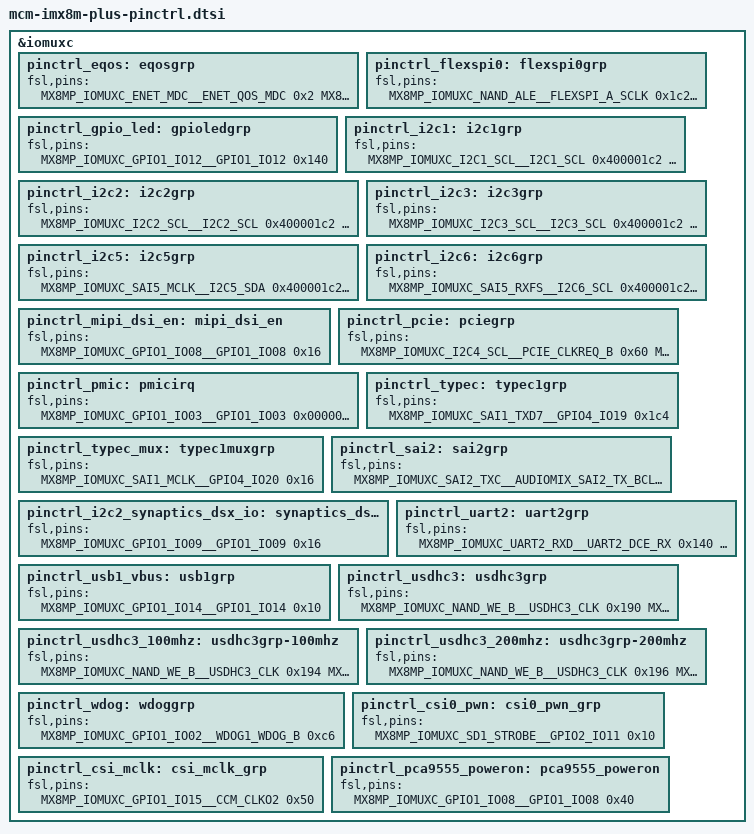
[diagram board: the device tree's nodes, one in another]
#include <dt-bindings/usb/pd.h>
#include "../freescale/imx8mp.dtsi"

&iomuxc {

	pinctrl_eqos: eqosgrp {
		fsl,pins = <
			MX8MP_IOMUXC_ENET_MDC__ENET_QOS_MDC	0x2
			MX8MP_IOMUXC_ENET_MDIO__ENET_QOS_MDIO	0x2
			MX8MP_IOMUXC_ENET_RD0__ENET_QOS_RGMII_RD0	0x90
			MX8MP_IOMUXC_ENET_RD1__ENET_QOS_RGMII_RD1	0x90
			MX8MP_IOMUXC_ENET_RD2__ENET_QOS_RGMII_RD2	0x90
			MX8MP_IOMUXC_ENET_RD3__ENET_QOS_RGMII_RD3	0x90
			MX8MP_IOMUXC_ENET_RXC__CCM_ENET_QOS_CLOCK_GENERATE_RX_CLK	0x90
			MX8MP_IOMUXC_ENET_RX_CTL__ENET_QOS_RGMII_RX_CTL	0x90
			MX8MP_IOMUXC_ENET_TD0__ENET_QOS_RGMII_TD0		0x16
			MX8MP_IOMUXC_ENET_TD1__ENET_QOS_RGMII_TD1		0x16
			MX8MP_IOMUXC_ENET_TD2__ENET_QOS_RGMII_TD2		0x16
			MX8MP_IOMUXC_ENET_TD3__ENET_QOS_RGMII_TD3		0x16
			MX8MP_IOMUXC_ENET_TX_CTL__ENET_QOS_RGMII_TX_CTL	0x16
			MX8MP_IOMUXC_ENET_TXC__CCM_ENET_QOS_CLOCK_GENERATE_TX_CLK	0x16
			MX8MP_IOMUXC_GPIO1_IO10__GPIO1_IO10				0x10
		>;
	};

	pinctrl_flexspi0: flexspi0grp {
		fsl,pins = <
			MX8MP_IOMUXC_NAND_ALE__FLEXSPI_A_SCLK		0x1c2
			MX8MP_IOMUXC_NAND_CE0_B__FLEXSPI_A_SS0_B	0x82
			MX8MP_IOMUXC_NAND_DATA00__FLEXSPI_A_DATA00	0x82
			MX8MP_IOMUXC_NAND_DATA01__FLEXSPI_A_DATA01	0x82
			MX8MP_IOMUXC_NAND_DATA02__FLEXSPI_A_DATA02	0x82
			MX8MP_IOMUXC_NAND_DATA03__FLEXSPI_A_DATA03	0x82
		>;
	};

	pinctrl_gpio_led: gpioledgrp {
		fsl,pins = <
			MX8MP_IOMUXC_GPIO1_IO12__GPIO1_IO12	0x140
		>;
	};

	pinctrl_i2c1: i2c1grp {
		fsl,pins = <
			MX8MP_IOMUXC_I2C1_SCL__I2C1_SCL		0x400001c2
			MX8MP_IOMUXC_I2C1_SDA__I2C1_SDA		0x400001c2
		>;
	};

	pinctrl_i2c2: i2c2grp {
		fsl,pins = <
			MX8MP_IOMUXC_I2C2_SCL__I2C2_SCL			0x400001c2
			MX8MP_IOMUXC_I2C2_SDA__I2C2_SDA			0x400001c2
		>;
	};

	pinctrl_i2c3: i2c3grp {
		fsl,pins = <
			MX8MP_IOMUXC_I2C3_SCL__I2C3_SCL			0x400001c2
			MX8MP_IOMUXC_I2C3_SDA__I2C3_SDA			0x400001c2
		>;
	};

	pinctrl_i2c5: i2c5grp {
		fsl,pins = <
			MX8MP_IOMUXC_SAI5_MCLK__I2C5_SDA		0x400001c2
			MX8MP_IOMUXC_SAI5_RXD0__I2C5_SCL		0x400001c2
		>;
	};

	pinctrl_i2c6: i2c6grp {
		fsl,pins = <
			MX8MP_IOMUXC_SAI5_RXFS__I2C6_SCL		0x400001c2
			MX8MP_IOMUXC_SAI5_RXC__I2C6_SDA			0x400001c2
		>;
	};

	pinctrl_mipi_dsi_en: mipi_dsi_en {
		fsl,pins = <
			MX8MP_IOMUXC_GPIO1_IO08__GPIO1_IO08	0x16
		>;
	};

	pinctrl_pcie: pciegrp {
		fsl,pins = <
			MX8MP_IOMUXC_I2C4_SCL__PCIE_CLKREQ_B		0x60
			MX8MP_IOMUXC_I2C4_SDA__GPIO5_IO21		0x10
		>;
	};

	pinctrl_pmic: pmicirq {
		fsl,pins = <
			MX8MP_IOMUXC_GPIO1_IO03__GPIO1_IO03	0x000001c0
		>;
	};

	pinctrl_typec: typec1grp {
		fsl,pins = <
			MX8MP_IOMUXC_SAI1_TXD7__GPIO4_IO19	0x1c4
		>;
	};

	pinctrl_typec_mux: typec1muxgrp {
		fsl,pins = <
			MX8MP_IOMUXC_SAI1_MCLK__GPIO4_IO20	0x16
		>;
	};

	pinctrl_sai2: sai2grp {
		fsl,pins = <
			MX8MP_IOMUXC_SAI2_TXC__AUDIOMIX_SAI2_TX_BCLK	0xd6
			MX8MP_IOMUXC_SAI2_TXFS__AUDIOMIX_SAI2_TX_SYNC	0xd6
			MX8MP_IOMUXC_SAI2_TXD0__AUDIOMIX_SAI2_TX_DATA00	0xd6
			MX8MP_IOMUXC_SAI2_RXD0__AUDIOMIX_SAI2_RX_DATA00	0xd6
		>;
	};

	pinctrl_i2c2_synaptics_dsx_io: synaptics_dsx_iogrp {
		fsl,pins = <
			MX8MP_IOMUXC_GPIO1_IO09__GPIO1_IO09		0x16
		>;
	};

	pinctrl_uart2: uart2grp {
		fsl,pins = <
			MX8MP_IOMUXC_UART2_RXD__UART2_DCE_RX	0x140
			MX8MP_IOMUXC_UART2_TXD__UART2_DCE_TX	0x140
		>;
	};

	pinctrl_usb1_vbus: usb1grp {
		fsl,pins = <
			MX8MP_IOMUXC_GPIO1_IO14__GPIO1_IO14	0x10
		>;
	};

	pinctrl_usdhc3: usdhc3grp {
		fsl,pins = <
			MX8MP_IOMUXC_NAND_WE_B__USDHC3_CLK	0x190
			MX8MP_IOMUXC_NAND_WP_B__USDHC3_CMD	0x1d0
			MX8MP_IOMUXC_NAND_DATA04__USDHC3_DATA0	0x1d0
			MX8MP_IOMUXC_NAND_DATA05__USDHC3_DATA1	0x1d0
			MX8MP_IOMUXC_NAND_DATA06__USDHC3_DATA2	0x1d0
			MX8MP_IOMUXC_NAND_DATA07__USDHC3_DATA3	0x1d0
			MX8MP_IOMUXC_NAND_RE_B__USDHC3_DATA4	0x1d0
			MX8MP_IOMUXC_NAND_CE2_B__USDHC3_DATA5	0x1d0
			MX8MP_IOMUXC_NAND_CE3_B__USDHC3_DATA6	0x1d0
			MX8MP_IOMUXC_NAND_CLE__USDHC3_DATA7	0x1d0
			MX8MP_IOMUXC_NAND_CE1_B__USDHC3_STROBE	0x190
		>;
	};

	pinctrl_usdhc3_100mhz: usdhc3grp-100mhz {
		fsl,pins = <
			MX8MP_IOMUXC_NAND_WE_B__USDHC3_CLK	0x194
			MX8MP_IOMUXC_NAND_WP_B__USDHC3_CMD	0x1d4
			MX8MP_IOMUXC_NAND_DATA04__USDHC3_DATA0	0x1d4
			MX8MP_IOMUXC_NAND_DATA05__USDHC3_DATA1	0x1d4
			MX8MP_IOMUXC_NAND_DATA06__USDHC3_DATA2	0x1d4
			MX8MP_IOMUXC_NAND_DATA07__USDHC3_DATA3	0x1d4
			MX8MP_IOMUXC_NAND_RE_B__USDHC3_DATA4	0x1d4
			MX8MP_IOMUXC_NAND_CE2_B__USDHC3_DATA5	0x1d4
			MX8MP_IOMUXC_NAND_CE3_B__USDHC3_DATA6	0x1d4
			MX8MP_IOMUXC_NAND_CLE__USDHC3_DATA7	0x1d4
			MX8MP_IOMUXC_NAND_CE1_B__USDHC3_STROBE	0x194
		>;
	};

	pinctrl_usdhc3_200mhz: usdhc3grp-200mhz {
		fsl,pins = <
			MX8MP_IOMUXC_NAND_WE_B__USDHC3_CLK	0x196
			MX8MP_IOMUXC_NAND_WP_B__USDHC3_CMD	0x1d6
			MX8MP_IOMUXC_NAND_DATA04__USDHC3_DATA0	0x1d6
			MX8MP_IOMUXC_NAND_DATA05__USDHC3_DATA1	0x1d6
			MX8MP_IOMUXC_NAND_DATA06__USDHC3_DATA2	0x1d6
			MX8MP_IOMUXC_NAND_DATA07__USDHC3_DATA3	0x1d6
			MX8MP_IOMUXC_NAND_RE_B__USDHC3_DATA4	0x1d6
			MX8MP_IOMUXC_NAND_CE2_B__USDHC3_DATA5	0x1d6
			MX8MP_IOMUXC_NAND_CE3_B__USDHC3_DATA6	0x1d6
			MX8MP_IOMUXC_NAND_CLE__USDHC3_DATA7	0x1d6
			MX8MP_IOMUXC_NAND_CE1_B__USDHC3_STROBE	0x196
		>;
	};

	pinctrl_wdog: wdoggrp {
		fsl,pins = <
			MX8MP_IOMUXC_GPIO1_IO02__WDOG1_WDOG_B	0xc6
		>;
	};

	pinctrl_csi0_pwn: csi0_pwn_grp {
		fsl,pins = <
			MX8MP_IOMUXC_SD1_STROBE__GPIO2_IO11	0x10
		>;
	};

	pinctrl_csi_mclk: csi_mclk_grp {
		fsl,pins = <
			MX8MP_IOMUXC_GPIO1_IO15__CCM_CLKO2	0x50
		>;
	};

	pinctrl_pca9555_poweron: pca9555_poweron {
		fsl,pins = <
			MX8MP_IOMUXC_GPIO1_IO08__GPIO1_IO08	0x40
		>;
	};
};
